# BL702 register map
Vendor: Bouffalo Lab; Series: WiFi BT; File version: 1.0
BL702 BLE + Zigbee combo chipset
Registers are 32-bit, read-write, reset 0x0 unless marked. A register's access mark holds for its fields unless they carry their own. Offsets are from the block's base; lines under a group give offsets from that group; [hi:lo] are bit positions; {n}, {i} and the like mark numbered series; 'fields as' and 'values as' point back to an identical list; <NAME> marks a mode.

## Memory map
0x40000000 GLB size 0x1000 — Global control register
0x40001000 MIX size 0x1000 — RF mixed signal registers
0x40002000 GPIP size 0x1000 — General purpose DAC/ADC/ACOMP interface control
0x40003000 SEC_DBG size 0x1000 — Security Debug
0x40004000 SEC_ENG size 0x1000 — Security Engine
0x40005000 TZC_SEC size 0x1000 — Trustzone control security
0x40006000 TZC_NSEC size 0x1000 — Trustzone control non-security
0x40007000 ef_data_0 size 0x1000
0x40007000 ef_data_1 size 0x1000
0x40007000 ef_ctrl size 0x1000
0x40007000 DMA size 0x1000 — DMA control
0x40008000 CCI size 0x1000
0x40009000 L1C size 0x1000 — Cache control
0x4000A000 UART0 size 0x100 — UART control
0x4000A100 UART1 size 0x100
0x4000A200 SPI size 0x100 — SPI master/slave control
0x4000A300 I2C size 0x100 — I2C control
0x4000A400 PWM size 0x100 — Pulse Width Modulation *5 control
0x4000A500 TIMER size 0x100 — Timer control
0x4000A600 IR size 0x100 — IR Remote control
0x4000A700 CKS size 0x100 — Checksum
0x4000A800 QDEC0 size 0x40 — Quadrature decoder control
0x4000A840 QDEC1 size 0x40
0x4000A880 QDEC2 size 0x40
0x4000AA00 I2S size 0x100 — I2S control
0x4000AB00 KYS size 0x100 — Key-scan control
0x4000AD00 CAM size 0x1000
0x4000AE00 MJPEG size 0x1000
0x4000B000 SF_CTRL size 0x1000 — Flash/pSRAM control
0x4000D000 EMAC size 0x800 — Ethernet MAC control
0x4000D800 USB size 0x400 — USB control
0x4000E000 PDS size 0x1000 — Sleep control (Power Down Sleep)
0x4000F000 HBN size 0x1000 — Deep sleep control (Hibernate)
0x4000F000 AON size 0x1000
0x4C000000 M154 size 0x1000 — MAC 802.15.4 control

## Interrupts
16 BMX_ERR (GLB)
17 BMX_TO (GLB)
18 L1C_BMX_ERR (GLB)
19 L1C_BMX_TO (GLB)
20 SEC_BMX_ERR (GLB)
21 RF_TOP_INT0 (MIX)
22 RF_TOP_INT0 (MIX)
24 DMA_BMX_ERR (GLB)
25 SEC_GMAC (SEC_ENG)
26 SEC_CDET (SEC_ENG)
27 SEC_PKA (SEC_ENG)
28 SEC_TRNG (SEC_ENG)
29 SEC_AES (SEC_ENG)
30 SEC_SHA (SEC_ENG)
31 DMA_ALL (DMA)
32 MJPEG
33 CAM
34 I2S
35 IRTX (IR)
36 IRRX (IR)
37 USB
38 EMAC
39 SF_CTRL
41 GPADC_DMA (GPIP)
42 EFUSE (ef_ctrl)
43 SPI
45 UART0
46 UART1
48 I2C
50 PWM
52 TIMER_CH0 (TIMER)
53 TIMER_CH1 (TIMER)
54 TIMER_WDT (TIMER)
55 KYS
56 QDEC0
57 QDEC1
58 QDEC2
60 GPIO_INT0 (GLB)
61 TOUCH (GLB)
63 M154_REQ_ENH_ACK (M154)
64 M154
65 M154_AES (M154)
66 PDS_WAKEUP (PDS)
67 HBN_OUT0 (HBN)
68 HBN_OUT1 (HBN)
69 BOR (AON)

## M154 — MAC 802.15.4 control
Base 0x4C000000
0x90 csma — Enable CSMA on TX
  [0] enable
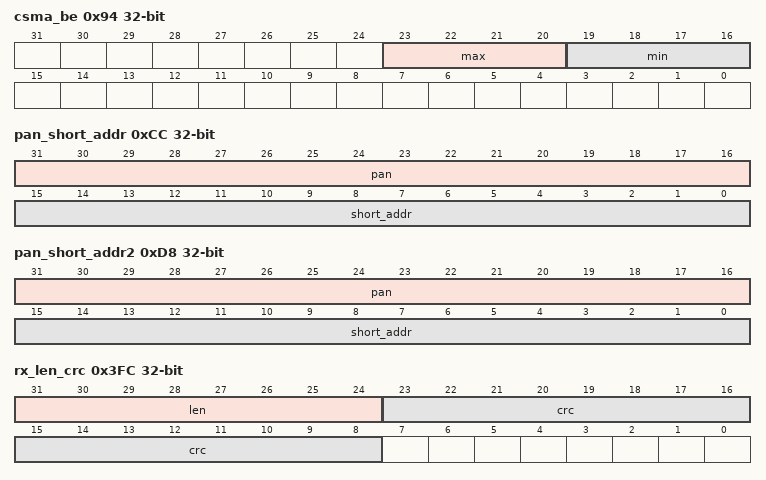
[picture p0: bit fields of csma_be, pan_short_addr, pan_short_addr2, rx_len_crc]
0x94 csma_be — CSMA backoff exponent
  [23:20] max — Maximum backoff exponent, valid range [3, 8]
  [19:16] min — Minimum backoff exponent, valid range [0, max]
0xCC pan_short_addr — PAN ID and short address
  [31:16] pan, [15:0] short_addr
{0xD0+4i} long_addr[{i}] (i=0..1) — Long address
0xD8 pan_short_addr2 — Second PAN ID and short address
  [31:16] pan, [15:0] short_addr
{0xDC+4i} long_addr2[{i}] (i=0..1) — Second long address
  [31:0] addr
{0x200+4i} tx_buffer[{i}] (i=0..62) — transmit data buffer
  [31:0] data
0x2FC tx_len — TX frame length, including 2 extra bytes (checksum?)
  [31:24] frame_length
0x300 tx_data_rate
  [9:0] data_rate
    167=DATA_RATE_250K (250 kbit/s); 0x1E1=DATA_RATE_500K (500 kbit/s); 0x228=DATA_RATE_1M (1000 kbit/s); 0x3F6=DATA_RATE_2M (2000 kbit/s)
0x3FC rx_len_crc — Length and CRC of received frame
  [31:24] len, [23:8] crc
{0x400+4i} rx_buffer[{i}] (i=0..62) — received data buffer
  [31:0] data
0x500 rx_data_rate — used in lmac154_getRxDataRate
  [1:0] data_rate

## GPIP — General purpose DAC/ADC/ACOMP interface control
Base 0x40002000
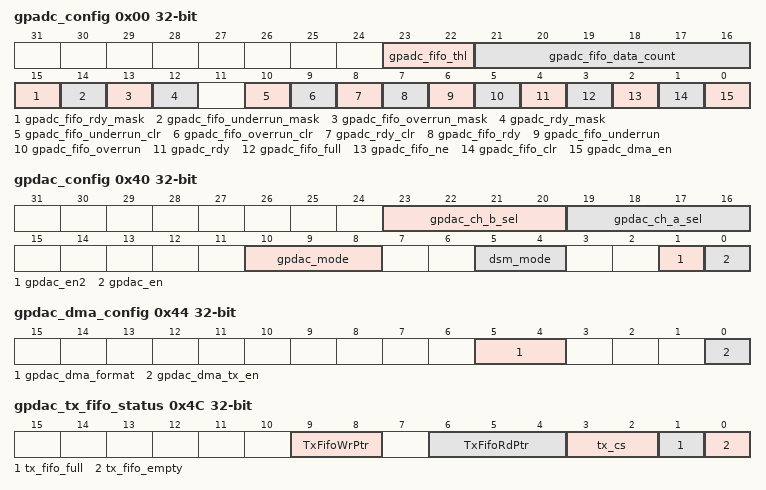
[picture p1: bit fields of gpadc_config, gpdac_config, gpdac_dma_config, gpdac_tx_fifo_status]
0x00 gpadc_config
  [23:22] gpadc_fifo_thl, [21:16] gpadc_fifo_data_count, [15] gpadc_fifo_rdy_mask, [14] gpadc_fifo_underrun_mask, [13] gpadc_fifo_overrun_mask, [12] gpadc_rdy_mask, [10] gpadc_fifo_underrun_clr, [9] gpadc_fifo_overrun_clr, [8] gpadc_rdy_clr, [7] gpadc_fifo_rdy, [6] gpadc_fifo_underrun, [5] gpadc_fifo_overrun, [4] gpadc_rdy, [3] gpadc_fifo_full, [2] gpadc_fifo_ne, [1] gpadc_fifo_clr, [0] gpadc_dma_en
0x04 gpadc_dma_rdata
  [25:0] gpadc_dma_rdata
0x40 gpdac_config
  [23:20] gpdac_ch_b_sel, [19:16] gpdac_ch_a_sel, [10:8] gpdac_mode, [5:4] dsm_mode, [1] gpdac_en2, [0] gpdac_en
0x44 gpdac_dma_config
  [5:4] gpdac_dma_format, [0] gpdac_dma_tx_en
0x48 gpdac_dma_wdata
0x4C gpdac_tx_fifo_status
  [9:8] TxFifoWrPtr, [6:4] TxFifoRdPtr, [3:2] tx_cs, [1] tx_fifo_full, [0] tx_fifo_empty
